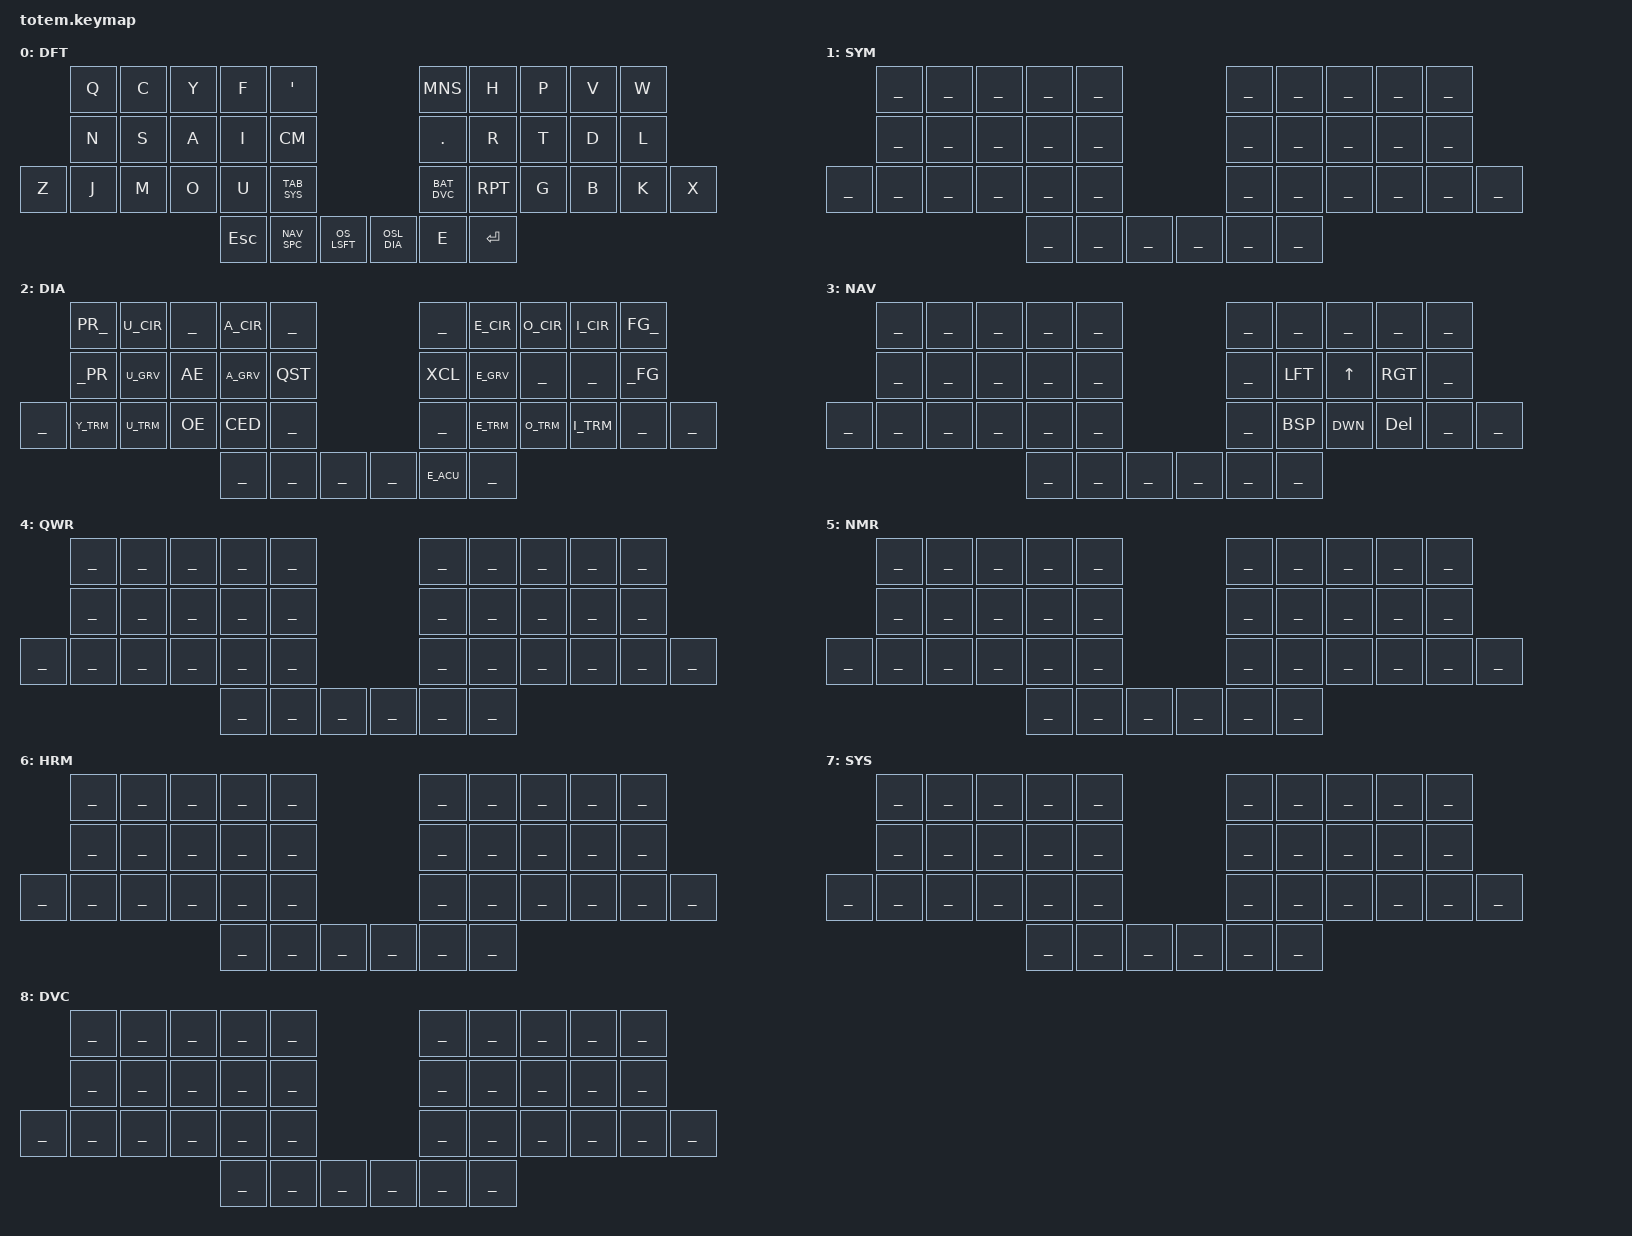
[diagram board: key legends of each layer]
//
//                                                        ▀▀▀▀▀     ▀▀▀▀▀          ▀▀█▀▀
//                                                        ▄▀▀▀▄  ▄  ▄▀▀▀▄  ▄  ▄▀▀▀▄  █  ▄▀▀▀▄
//                                                        █   █  █  █   █  █  █   █  █  █   █
//                                                         ▀▀▀   █   ▀▀▀   █   ▀▀▀   ▀   ▀▀▀
//                                                               █      ▄▄▄█▄▄▄    █   █
//                                                               ▀      █  █  █     █▄█
//                                                             ▀▀▀▀▀    █  █  █      ▀
//                                                                      ▀  ▀  ▀
//
// ▄▄▄▄▄▄▄▄▄▄▄▄▄▄▄▄▄▄▄▄▄▄▄▄▄▄▄▄▄▄▄▄▄▄▄▄▄▄▄▄▄▄▄▄▄▄▄▄▄▄▄▄▄▄▄▄▄▄▄▄▄▄▄▄▄▄▄▄▄▄▄▄▄▄▄▄▄▄▄▄▄▄▄▄▄▄▄▄▄▄▄▄▄▄▄▄▄▄▄▄▄▄▄▄▄▄▄▄▄▄▄▄▄▄▄▄▄▄▄▄▄▄▄▄▄▄▄▄▄▄▄▄▄▄▄▄▄▄▄▄▄▄▄▄▄▄▄▄▄

#include <behaviors.dtsi>
#include <dt-bindings/zmk/bt.h>
#include <dt-bindings/zmk/keys.h>
#include <dt-bindings/zmk/outputs.h>

#include "defaults.h"
#include "includes/aliases.dtsi"
#include "includes/mappings.dtsi"
#include "includes/behaviors.dtsi"
// #include "includes/macros.dtsi"
#include "includes/combos.dtsi"

#define DFT 0
#define SYM 1
#define DIA 2
#define NAV 3
#define QWR 4
#define NMR 5
#define HMR 6
#define SYS 7
#define DVC 8


&mt {
    quick-tap-ms = <100>;
    global-quick-tap;
    flavor = "tap-preferred";
    tapping-term-ms = <170>;
};

/ {

    keymap {
        compatible = "zmk,keymap";

        Default {
//    ┏━━━━━━━━━━━━━━━━━━━━━━━━━━━━━━━━━━━━━━┓
                display-name= "DFT"          ;
//    ┗━━━━━━━━━━━━━━━━━━━━━━━━━━━━━━━━━━━━━━┛

            bindings = <
//  ╷           ╷           ╷           ╷           ╷           ╷           ╷           ╷   ╷           ╷           ╷           ╷           ╷           ╷           ╷           ╷
//              ┏━━━━━━━━━━━┳━━━━━━━━━━━┳━━━━━━━━━━━┳━━━━━━━━━━━┳━━━━━━━━━━━┓                           ┏━━━━━━━━━━━┳━━━━━━━━━━━┳━━━━━━━━━━━┳━━━━━━━━━━━┳━━━━━━━━━━━┓
                    &kp Q       &kp C       &kp Y       &kp F       &kp SQT                                 &kp MNS     &kp H       &kp P       &kp V       &kp W
//              ┣━━━━━━━━━━━╋━━━━━━━━━━━╋━━━━━━━━━━━╋━━━━━━━━━━━╋━━━━━━━━━━━┫                           ┣━━━━━━━━━━━╋━━━━━━━━━━━╋━━━━━━━━━━━╋━━━━━━━━━━━╋━━━━━━━━━━━┫
                    &kp N       &kp S       &kp A       &kp I       &kp CM                                  &kp DOT     &kp R       &kp T       &kp D       &kp L
//  ┏━━━━━━━━━━━╋━━━━━━━━━━━╋━━━━━━━━━━━╋━━━━━━━━━━━╋━━━━━━━━━━━╋━━━━━━━━━━━┫                           ┣━━━━━━━━━━━╋━━━━━━━━━━━╋━━━━━━━━━━━╋━━━━━━━━━━━╋━━━━━━━━━━━╋━━━━━━━━━━━┓
        &kp Z       &kp J       &kp M       &kp O       &kp U       TAB_SYS                                 BAT_DVC     RPT         &kp G       &kp B       &kp K       &kp X
//  ┗━━━━━━━━━━━┻━━━━━━━━━━━┻━━━━━━━━━━━┗━━━━━━━━━━━╋━━━━━━━━━━━╋━━━━━━━━━━━┫━━━━━━━━━━━┓   ┏━━━━━━━━━━━┣━━━━━━━━━━━╋━━━━━━━━━━━╋━━━━━━━━━━━┛━━━━━━━━━━━┻━━━━━━━━━━━┻━━━━━━━━━━━┛
                                                        &kp ESC     NAV_SPC     OS_LSFT         OSL_DIA     &kp E      &kp RET
//                                                  ┗━━━━━━━━━━━┻━━━━━━━━━━━┻━━━━━━━━━━━┛   ┗━━━━━━━━━━━┻━━━━━━━━━━━┻━━━━━━━━━━━┛
            >;
        }; // end Default


        Symbols {
//    ┏━━━━━━━━━━━━━━━━━━━━━━━━━━━━━━━━━━━━━━┓
            display-name= "SYM"              ;
//    ┗━━━━━━━━━━━━━━━━━━━━━━━━━━━━━━━━━━━━━━┛

            bindings = <
//  ╷           ╷           ╷           ╷           ╷           ╷           ╷           ╷   ╷           ╷          ╷            ╷           ╷           ╷           ╷           ╷
//              ┏━━━━━━━━━━━┳━━━━━━━━━━━┳━━━━━━━━━━━┳━━━━━━━━━━━┳━━━━━━━━━━━┓                           ┏━━━━━━━━━━━┳━━━━━━━━━━━┳━━━━━━━━━━━┳━━━━━━━━━━━┳━━━━━━━━━━━┓
                    ___         ___         ___         ___         ___                                     ___         ___         ___         ___         ___
//              ┣━━━━━━━━━━━╋━━━━━━━━━━━╋━━━━━━━━━━━╋━━━━━━━━━━━╋━━━━━━━━━━━┫                           ┣━━━━━━━━━━━╋━━━━━━━━━━━╋━━━━━━━━━━━╋━━━━━━━━━━━╋━━━━━━━━━━━┫
                    ___         ___         ___         ___         ___                                     ___         ___         ___         ___         ___
//  ┏━━━━━━━━━━━╋━━━━━━━━━━━╋━━━━━━━━━━━╋━━━━━━━━━━━╋━━━━━━━━━━━╋━━━━━━━━━━━┫                           ┣━━━━━━━━━━━╋━━━━━━━━━━━╋━━━━━━━━━━━╋━━━━━━━━━━━╋━━━━━━━━━━━╋━━━━━━━━━━━┓
        ___         ___         ___         ___         ___         ___                                     ___         ___         ___         ___         ___         ___
//  ┗━━━━━━━━━━━┻━━━━━━━━━━━┻━━━━━━━━━━━┗━━━━━━━━━━━╋━━━━━━━━━━━╋━━━━━━━━━━━┫━━━━━━━━━━━┓   ┏━━━━━━━━━━━┣━━━━━━━━━━━╋━━━━━━━━━━━╋━━━━━━━━━━━┛━━━━━━━━━━━┻━━━━━━━━━━━┻━━━━━━━━━━━┛
                                                        ___         ___         ___             ___         ___         ___
//                                                  ┗━━━━━━━━━━━┻━━━━━━━━━━━┻━━━━━━━━━━━┛   ┗━━━━━━━━━━━┻━━━━━━━━━━━┻━━━━━━━━━━━┛
            >;
        };  // end Symbols


        Diacritics {
//    ┏━━━━━━━━━━━━━━━━━━━━━━━━━━━━━━━━━━━━━━┓
            display-name= "DIA"              ;
//    ┗━━━━━━━━━━━━━━━━━━━━━━━━━━━━━━━━━━━━━━┛

            bindings = <
//  ╷           ╷           ╷           ╷           ╷           ╷           ╷           ╷   ╷           ╷          ╷            ╷           ╷           ╷           ╷           ╷
//              ┏━━━━━━━━━━━┳━━━━━━━━━━━┳━━━━━━━━━━━┳━━━━━━━━━━━┳━━━━━━━━━━━┓                           ┏━━━━━━━━━━━┳━━━━━━━━━━━┳━━━━━━━━━━━┳━━━━━━━━━━━┳━━━━━━━━━━━┓
                    &kp PR_     U_CIR       ___         A_CIR       ___                                     ___         E_CIR       O_CIR       I_CIR       &kp FG_
//              ┣━━━━━━━━━━━╋━━━━━━━━━━━╋━━━━━━━━━━━╋━━━━━━━━━━━╋━━━━━━━━━━━┫                           ┣━━━━━━━━━━━╋━━━━━━━━━━━╋━━━━━━━━━━━╋━━━━━━━━━━━╋━━━━━━━━━━━┫
                    &kp _PR     U_GRV       &kp AE      A_GRV       &kp QST                                 &kp XCL     E_GRV       ___         ___         &kp _FG
//  ┏━━━━━━━━━━━╋━━━━━━━━━━━╋━━━━━━━━━━━╋━━━━━━━━━━━╋━━━━━━━━━━━╋━━━━━━━━━━━┫                           ┣━━━━━━━━━━━╋━━━━━━━━━━━╋━━━━━━━━━━━╋━━━━━━━━━━━╋━━━━━━━━━━━╋━━━━━━━━━━━┓
        ___         Y_TRM       U_TRM       &kp OE      &kp C_CED   ___                                     ___         E_TRM       O_TRM       I_TRM       ___         ___
//  ┗━━━━━━━━━━━┻━━━━━━━━━━━┻━━━━━━━━━━━┗━━━━━━━━━━━╋━━━━━━━━━━━╋━━━━━━━━━━━┫━━━━━━━━━━━┓   ┏━━━━━━━━━━━┣━━━━━━━━━━━╋━━━━━━━━━━━╋━━━━━━━━━━━┛━━━━━━━━━━━┻━━━━━━━━━━━┻━━━━━━━━━━━┛
                                                        ___         ___         ___             ___         E_ACU       ___
//                                                  ┗━━━━━━━━━━━┻━━━━━━━━━━━┻━━━━━━━━━━━┛   ┗━━━━━━━━━━━┻━━━━━━━━━━━┻━━━━━━━━━━━┛
            >;
        };  // end Diacritics


        Navigation {
//    ┏━━━━━━━━━━━━━━━━━━━━━━━━━━━━━━━━━━━━━━┓
            display-name= "NAV"              ;
//    ┗━━━━━━━━━━━━━━━━━━━━━━━━━━━━━━━━━━━━━━┛

            bindings = <
//  ╷           ╷           ╷           ╷           ╷           ╷           ╷           ╷   ╷           ╷          ╷            ╷           ╷           ╷           ╷           ╷
//              ┏━━━━━━━━━━━┳━━━━━━━━━━━┳━━━━━━━━━━━┳━━━━━━━━━━━┳━━━━━━━━━━━┓                           ┏━━━━━━━━━━━┳━━━━━━━━━━━┳━━━━━━━━━━━┳━━━━━━━━━━━┳━━━━━━━━━━━┓
                    ___         ___         ___         ___         ___                                     ___         ___         ___         ___         ___
//              ┣━━━━━━━━━━━╋━━━━━━━━━━━╋━━━━━━━━━━━╋━━━━━━━━━━━╋━━━━━━━━━━━┫                           ┣━━━━━━━━━━━╋━━━━━━━━━━━╋━━━━━━━━━━━╋━━━━━━━━━━━╋━━━━━━━━━━━┫
                    ___         ___         ___         ___         ___                                     ___        &kp LFT     &kp UP      &kp RGT      ___
//  ┏━━━━━━━━━━━╋━━━━━━━━━━━╋━━━━━━━━━━━╋━━━━━━━━━━━╋━━━━━━━━━━━╋━━━━━━━━━━━┫                           ┣━━━━━━━━━━━╋━━━━━━━━━━━╋━━━━━━━━━━━╋━━━━━━━━━━━╋━━━━━━━━━━━╋━━━━━━━━━━━┓
        ___         ___         ___         ___         ___         ___                                     ___        &kp BSP     &kp DWN     &kp DEL      ___         ___
//  ┗━━━━━━━━━━━┻━━━━━━━━━━━┻━━━━━━━━━━━┗━━━━━━━━━━━╋━━━━━━━━━━━╋━━━━━━━━━━━┫━━━━━━━━━━━┓   ┏━━━━━━━━━━━┣━━━━━━━━━━━╋━━━━━━━━━━━╋━━━━━━━━━━━┛━━━━━━━━━━━┻━━━━━━━━━━━┻━━━━━━━━━━━┛
                                                        ___         ___         ___             ___         ___         ___
//                                                  ┗━━━━━━━━━━━┻━━━━━━━━━━━┻━━━━━━━━━━━┛   ┗━━━━━━━━━━━┻━━━━━━━━━━━┻━━━━━━━━━━━┛
            >;
        };  // end Navigation


        Qwerty {
//    ┏━━━━━━━━━━━━━━━━━━━━━━━━━━━━━━━━━━━━━━┓
            display-name= "QWR"              ;
//    ┗━━━━━━━━━━━━━━━━━━━━━━━━━━━━━━━━━━━━━━┛

            bindings = <
//  ╷           ╷           ╷           ╷           ╷           ╷           ╷           ╷   ╷           ╷          ╷            ╷           ╷           ╷           ╷           ╷
//              ┏━━━━━━━━━━━┳━━━━━━━━━━━┳━━━━━━━━━━━┳━━━━━━━━━━━┳━━━━━━━━━━━┓                           ┏━━━━━━━━━━━┳━━━━━━━━━━━┳━━━━━━━━━━━┳━━━━━━━━━━━┳━━━━━━━━━━━┓
                    ___         ___         ___         ___         ___                                     ___         ___         ___         ___         ___
//              ┣━━━━━━━━━━━╋━━━━━━━━━━━╋━━━━━━━━━━━╋━━━━━━━━━━━╋━━━━━━━━━━━┫                           ┣━━━━━━━━━━━╋━━━━━━━━━━━╋━━━━━━━━━━━╋━━━━━━━━━━━╋━━━━━━━━━━━┫
                    ___         ___         ___         ___         ___                                     ___         ___         ___         ___         ___
//  ┏━━━━━━━━━━━╋━━━━━━━━━━━╋━━━━━━━━━━━╋━━━━━━━━━━━╋━━━━━━━━━━━╋━━━━━━━━━━━┫                           ┣━━━━━━━━━━━╋━━━━━━━━━━━╋━━━━━━━━━━━╋━━━━━━━━━━━╋━━━━━━━━━━━╋━━━━━━━━━━━┓
        ___         ___         ___         ___         ___         ___                                     ___         ___         ___         ___         ___         ___
//  ┗━━━━━━━━━━━┻━━━━━━━━━━━┻━━━━━━━━━━━┗━━━━━━━━━━━╋━━━━━━━━━━━╋━━━━━━━━━━━┫━━━━━━━━━━━┓   ┏━━━━━━━━━━━┣━━━━━━━━━━━╋━━━━━━━━━━━╋━━━━━━━━━━━┛━━━━━━━━━━━┻━━━━━━━━━━━┻━━━━━━━━━━━┛
                                                        ___         ___         ___             ___         ___         ___
//                                                  ┗━━━━━━━━━━━┻━━━━━━━━━━━┻━━━━━━━━━━━┛   ┗━━━━━━━━━━━┻━━━━━━━━━━━┻━━━━━━━━━━━┛
            >;
        };  // end Qwerty


        Numrow {
//    ┏━━━━━━━━━━━━━━━━━━━━━━━━━━━━━━━━━━━━━━┓
            display-name= "NMR"              ;
//    ┗━━━━━━━━━━━━━━━━━━━━━━━━━━━━━━━━━━━━━━┛

            bindings = <
//  ╷           ╷           ╷           ╷           ╷           ╷           ╷           ╷   ╷           ╷          ╷            ╷           ╷           ╷           ╷           ╷
//              ┏━━━━━━━━━━━┳━━━━━━━━━━━┳━━━━━━━━━━━┳━━━━━━━━━━━┳━━━━━━━━━━━┓                           ┏━━━━━━━━━━━┳━━━━━━━━━━━┳━━━━━━━━━━━┳━━━━━━━━━━━┳━━━━━━━━━━━┓
                    ___         ___         ___         ___         ___                                     ___         ___         ___         ___         ___
//              ┣━━━━━━━━━━━╋━━━━━━━━━━━╋━━━━━━━━━━━╋━━━━━━━━━━━╋━━━━━━━━━━━┫                           ┣━━━━━━━━━━━╋━━━━━━━━━━━╋━━━━━━━━━━━╋━━━━━━━━━━━╋━━━━━━━━━━━┫
                    ___         ___         ___         ___         ___                                     ___         ___         ___         ___         ___
//  ┏━━━━━━━━━━━╋━━━━━━━━━━━╋━━━━━━━━━━━╋━━━━━━━━━━━╋━━━━━━━━━━━╋━━━━━━━━━━━┫                           ┣━━━━━━━━━━━╋━━━━━━━━━━━╋━━━━━━━━━━━╋━━━━━━━━━━━╋━━━━━━━━━━━╋━━━━━━━━━━━┓
        ___         ___         ___         ___         ___         ___                                     ___         ___         ___         ___         ___         ___
//  ┗━━━━━━━━━━━┻━━━━━━━━━━━┻━━━━━━━━━━━┗━━━━━━━━━━━╋━━━━━━━━━━━╋━━━━━━━━━━━┫━━━━━━━━━━━┓   ┏━━━━━━━━━━━┣━━━━━━━━━━━╋━━━━━━━━━━━╋━━━━━━━━━━━┛━━━━━━━━━━━┻━━━━━━━━━━━┻━━━━━━━━━━━┛
                                                        ___         ___         ___             ___         ___         ___
//                                                  ┗━━━━━━━━━━━┻━━━━━━━━━━━┻━━━━━━━━━━━┛   ┗━━━━━━━━━━━┻━━━━━━━━━━━┻━━━━━━━━━━━┛
            >;
        };  // end Numrow


        HomerowMods {
//    ┏━━━━━━━━━━━━━━━━━━━━━━━━━━━━━━━━━━━━━━┓
            display-name= "HRM"              ;
//    ┗━━━━━━━━━━━━━━━━━━━━━━━━━━━━━━━━━━━━━━┛

            bindings = <
//  ╷           ╷           ╷           ╷           ╷           ╷           ╷           ╷   ╷           ╷          ╷            ╷           ╷           ╷           ╷           ╷
//              ┏━━━━━━━━━━━┳━━━━━━━━━━━┳━━━━━━━━━━━┳━━━━━━━━━━━┳━━━━━━━━━━━┓                           ┏━━━━━━━━━━━┳━━━━━━━━━━━┳━━━━━━━━━━━┳━━━━━━━━━━━┳━━━━━━━━━━━┓
                    ___         ___         ___         ___         ___                                     ___         ___         ___         ___         ___
//              ┣━━━━━━━━━━━╋━━━━━━━━━━━╋━━━━━━━━━━━╋━━━━━━━━━━━╋━━━━━━━━━━━┫                           ┣━━━━━━━━━━━╋━━━━━━━━━━━╋━━━━━━━━━━━╋━━━━━━━━━━━╋━━━━━━━━━━━┫
                    ___         ___         ___         ___         ___                                     ___         ___         ___         ___         ___
//  ┏━━━━━━━━━━━╋━━━━━━━━━━━╋━━━━━━━━━━━╋━━━━━━━━━━━╋━━━━━━━━━━━╋━━━━━━━━━━━┫                           ┣━━━━━━━━━━━╋━━━━━━━━━━━╋━━━━━━━━━━━╋━━━━━━━━━━━╋━━━━━━━━━━━╋━━━━━━━━━━━┓
        ___         ___         ___         ___         ___         ___                                     ___         ___         ___         ___         ___         ___
//  ┗━━━━━━━━━━━┻━━━━━━━━━━━┻━━━━━━━━━━━┗━━━━━━━━━━━╋━━━━━━━━━━━╋━━━━━━━━━━━┫━━━━━━━━━━━┓   ┏━━━━━━━━━━━┣━━━━━━━━━━━╋━━━━━━━━━━━╋━━━━━━━━━━━┛━━━━━━━━━━━┻━━━━━━━━━━━┻━━━━━━━━━━━┛
                                                        ___         ___         ___             ___         ___         ___
//                                                  ┗━━━━━━━━━━━┻━━━━━━━━━━━┻━━━━━━━━━━━┛   ┗━━━━━━━━━━━┻━━━━━━━━━━━┻━━━━━━━━━━━┛
            >;
        };  // end HomerowMods


        System {
//    ┏━━━━━━━━━━━━━━━━━━━━━━━━━━━━━━━━━━━━━━┓
            display-name= "SYS"              ;
//    ┗━━━━━━━━━━━━━━━━━━━━━━━━━━━━━━━━━━━━━━┛

            bindings = <
//  ╷           ╷           ╷           ╷           ╷           ╷           ╷           ╷   ╷           ╷          ╷            ╷           ╷           ╷           ╷           ╷
//              ┏━━━━━━━━━━━┳━━━━━━━━━━━┳━━━━━━━━━━━┳━━━━━━━━━━━┳━━━━━━━━━━━┓                           ┏━━━━━━━━━━━┳━━━━━━━━━━━┳━━━━━━━━━━━┳━━━━━━━━━━━┳━━━━━━━━━━━┓
                    ___         ___         ___         ___         ___                                     ___         ___         ___         ___         ___
//              ┣━━━━━━━━━━━╋━━━━━━━━━━━╋━━━━━━━━━━━╋━━━━━━━━━━━╋━━━━━━━━━━━┫                           ┣━━━━━━━━━━━╋━━━━━━━━━━━╋━━━━━━━━━━━╋━━━━━━━━━━━╋━━━━━━━━━━━┫
                    ___         ___         ___         ___         ___                                     ___         ___         ___         ___         ___
//  ┏━━━━━━━━━━━╋━━━━━━━━━━━╋━━━━━━━━━━━╋━━━━━━━━━━━╋━━━━━━━━━━━╋━━━━━━━━━━━┫                           ┣━━━━━━━━━━━╋━━━━━━━━━━━╋━━━━━━━━━━━╋━━━━━━━━━━━╋━━━━━━━━━━━╋━━━━━━━━━━━┓
        ___         ___         ___         ___         ___         ___                                     ___         ___         ___         ___         ___         ___
//  ┗━━━━━━━━━━━┻━━━━━━━━━━━┻━━━━━━━━━━━┗━━━━━━━━━━━╋━━━━━━━━━━━╋━━━━━━━━━━━┫━━━━━━━━━━━┓   ┏━━━━━━━━━━━┣━━━━━━━━━━━╋━━━━━━━━━━━╋━━━━━━━━━━━┛━━━━━━━━━━━┻━━━━━━━━━━━┻━━━━━━━━━━━┛
                                                        ___         ___         ___             ___         ___         ___
//                                                  ┗━━━━━━━━━━━┻━━━━━━━━━━━┻━━━━━━━━━━━┛   ┗━━━━━━━━━━━┻━━━━━━━━━━━┻━━━━━━━━━━━┛
            >;
        };  // end System


        Device {
//    ┏━━━━━━━━━━━━━━━━━━━━━━━━━━━━━━━━━━━━━━┓
            display-name= "DVC"              ;
//    ┗━━━━━━━━━━━━━━━━━━━━━━━━━━━━━━━━━━━━━━┛

            bindings = <
//  ╷           ╷           ╷           ╷           ╷           ╷           ╷           ╷   ╷           ╷          ╷            ╷           ╷           ╷           ╷           ╷
//              ┏━━━━━━━━━━━┳━━━━━━━━━━━┳━━━━━━━━━━━┳━━━━━━━━━━━┳━━━━━━━━━━━┓                           ┏━━━━━━━━━━━┳━━━━━━━━━━━┳━━━━━━━━━━━┳━━━━━━━━━━━┳━━━━━━━━━━━┓
                    ___         ___         ___         ___         ___                                     ___         ___         ___         ___         ___
//              ┣━━━━━━━━━━━╋━━━━━━━━━━━╋━━━━━━━━━━━╋━━━━━━━━━━━╋━━━━━━━━━━━┫                           ┣━━━━━━━━━━━╋━━━━━━━━━━━╋━━━━━━━━━━━╋━━━━━━━━━━━╋━━━━━━━━━━━┫
                    ___         ___         ___         ___         ___                                     ___         ___         ___         ___         ___
//  ┏━━━━━━━━━━━╋━━━━━━━━━━━╋━━━━━━━━━━━╋━━━━━━━━━━━╋━━━━━━━━━━━╋━━━━━━━━━━━┫                           ┣━━━━━━━━━━━╋━━━━━━━━━━━╋━━━━━━━━━━━╋━━━━━━━━━━━╋━━━━━━━━━━━╋━━━━━━━━━━━┓
        ___         ___         ___         ___         ___         ___                                     ___         ___         ___         ___         ___         ___
//  ┗━━━━━━━━━━━┻━━━━━━━━━━━┻━━━━━━━━━━━┗━━━━━━━━━━━╋━━━━━━━━━━━╋━━━━━━━━━━━┫━━━━━━━━━━━┓   ┏━━━━━━━━━━━┣━━━━━━━━━━━╋━━━━━━━━━━━╋━━━━━━━━━━━┛━━━━━━━━━━━┻━━━━━━━━━━━┻━━━━━━━━━━━┛
                                                        ___         ___         ___             ___         ___         ___
//                                                  ┗━━━━━━━━━━━┻━━━━━━━━━━━┻━━━━━━━━━━━┛   ┗━━━━━━━━━━━┻━━━━━━━━━━━┻━━━━━━━━━━━┛
            >;
        };  // end Device
    };
};
